# ioam3358 register map
Registers are 32-bit, access not given, no defined reset value unless marked. A register's access mark holds for its fields unless they carry their own. Addresses are absolute; registers are grouped by the start of their names; [hi:lo] are bit positions.

## UART5
0x481AA000 UART5_DLL 8-bit
0x481AA000 UART5_RHR 8-bit
0x481AA000 UART5_THR 8-bit
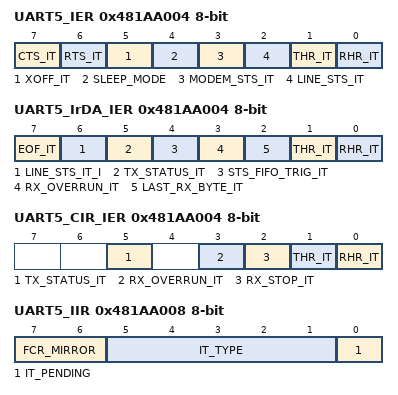
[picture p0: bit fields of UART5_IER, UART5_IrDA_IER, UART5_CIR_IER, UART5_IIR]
0x481AA004 UART5_IER 8-bit
  [7] CTS_IT, [6] RTS_IT, [5] XOFF_IT, [4] SLEEP_MODE, [3] MODEM_STS_IT, [2] LINE_STS_IT, [1] THR_IT, [0] RHR_IT
0x481AA004 UART5_DLH 8-bit
0x481AA004 UART5_IrDA_IER 8-bit
  [7] EOF_IT, [6] LINE_STS_IT_I, [5] TX_STATUS_IT, [4] STS_FIFO_TRIG_IT, [3] RX_OVERRUN_IT, [2] LAST_RX_BYTE_IT, [1] THR_IT, [0] RHR_IT
0x481AA004 UART5_CIR_IER 8-bit
  [5] TX_STATUS_IT, [3] RX_OVERRUN_IT, [2] RX_STOP_IT, [1] THR_IT, [0] RHR_IT
0x481AA008 UART5_IIR 8-bit
  [7:6] FCR_MIRROR, [5:1] IT_TYPE, [0] IT_PENDING
0x481AA008 UART5_FCR 8-bit
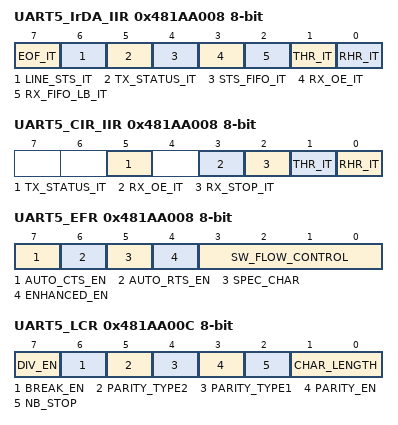
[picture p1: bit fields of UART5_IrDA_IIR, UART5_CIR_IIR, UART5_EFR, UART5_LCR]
0x481AA008 UART5_IrDA_IIR 8-bit
  [7] EOF_IT, [6] LINE_STS_IT, [5] TX_STATUS_IT, [4] STS_FIFO_IT, [3] RX_OE_IT, [2] RX_FIFO_LB_IT, [1] THR_IT, [0] RHR_IT
0x481AA008 UART5_CIR_IIR 8-bit
  [5] TX_STATUS_IT, [3] RX_OE_IT, [2] RX_STOP_IT, [1] THR_IT, [0] RHR_IT
0x481AA008 UART5_EFR 8-bit
  [7] AUTO_CTS_EN, [6] AUTO_RTS_EN, [5] SPEC_CHAR, [4] ENHANCED_EN, [3:0] SW_FLOW_CONTROL
0x481AA00C UART5_LCR 8-bit
  [7] DIV_EN, [6] BREAK_EN, [5] PARITY_TYPE2, [4] PARITY_TYPE1, [3] PARITY_EN, [2] NB_STOP, [1:0] CHAR_LENGTH
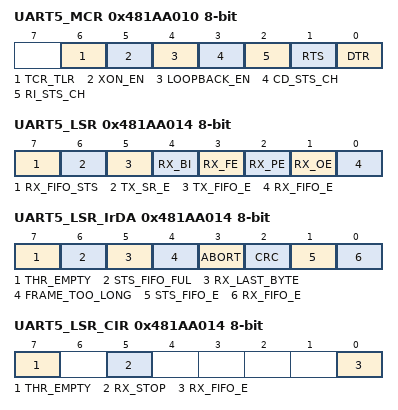
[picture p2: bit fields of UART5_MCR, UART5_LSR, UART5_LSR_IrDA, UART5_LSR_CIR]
0x481AA010 UART5_MCR 8-bit
  [6] TCR_TLR, [5] XON_EN, [4] LOOPBACK_EN, [3] CD_STS_CH, [2] RI_STS_CH, [1] RTS, [0] DTR
0x481AA010 UART5_XON1_ADDR1 8-bit
0x481AA014 UART5_LSR 8-bit
  [7] RX_FIFO_STS, [6] TX_SR_E, [5] TX_FIFO_E, [4] RX_BI, [3] RX_FE, [2] RX_PE, [1] RX_OE, [0] RX_FIFO_E
0x481AA014 UART5_XON2_ADDR2 8-bit
0x481AA014 UART5_LSR_IrDA 8-bit
  [7] THR_EMPTY, [6] STS_FIFO_FUL, [5] RX_LAST_BYTE, [4] FRAME_TOO_LONG, [3] ABORT, [2] CRC, [1] STS_FIFO_E, [0] RX_FIFO_E
0x481AA014 UART5_LSR_CIR 8-bit
  [7] THR_EMPTY, [5] RX_STOP, [0] RX_FIFO_E
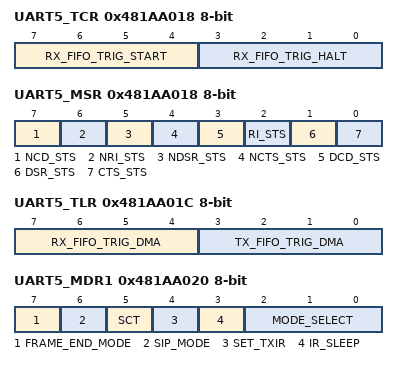
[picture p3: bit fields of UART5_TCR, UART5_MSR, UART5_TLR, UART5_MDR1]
0x481AA018 UART5_TCR 8-bit
  [7:4] RX_FIFO_TRIG_START, [3:0] RX_FIFO_TRIG_HALT
0x481AA018 UART5_XOFF1 8-bit
0x481AA018 UART5_MSR 8-bit
  [7] NCD_STS, [6] NRI_STS, [5] NDSR_STS, [4] NCTS_STS, [3] DCD_STS, [2] RI_STS, [1] DSR_STS, [0] CTS_STS
0x481AA01C UART5_TLR 8-bit
  [7:4] RX_FIFO_TRIG_DMA, [3:0] TX_FIFO_TRIG_DMA
0x481AA01C UART5_SPR 8-bit
0x481AA01C UART5_XOFF2 8-bit
0x481AA020 UART5_MDR1 8-bit
  [7] FRAME_END_MODE, [6] SIP_MODE, [5] SCT, [4] SET_TXIR, [3] IR_SLEEP, [2:0] MODE_SELECT
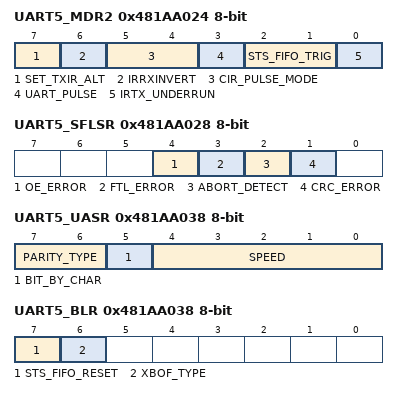
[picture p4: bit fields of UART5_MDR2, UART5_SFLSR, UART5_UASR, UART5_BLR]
0x481AA024 UART5_MDR2 8-bit
  [7] SET_TXIR_ALT, [6] IRRXINVERT, [5:4] CIR_PULSE_MODE, [3] UART_PULSE, [2:1] STS_FIFO_TRIG, [0] IRTX_UNDERRUN
0x481AA028 UART5_SFLSR 8-bit
  [4] OE_ERROR, [3] FTL_ERROR, [2] ABORT_DETECT, [1] CRC_ERROR
0x481AA028 UART5_TXFLL 8-bit
0x481AA02C UART5_TXFLH 8-bit
  [4:0] TXFLH
0x481AA02C UART5_RESUME 8-bit
0x481AA030 UART5_SFREGL 8-bit
0x481AA030 UART5_RXFLL 8-bit
0x481AA034 UART5_SFREGH 8-bit
  [3:0] SFREGH
0x481AA034 UART5_RXFLH 8-bit
  [3:0] RXFLH
0x481AA038 UART5_UASR 8-bit
  [7:6] PARITY_TYPE, [5] BIT_BY_CHAR, [4:0] SPEED
0x481AA038 UART5_BLR 8-bit
  [7] STS_FIFO_RESET, [6] XBOF_TYPE
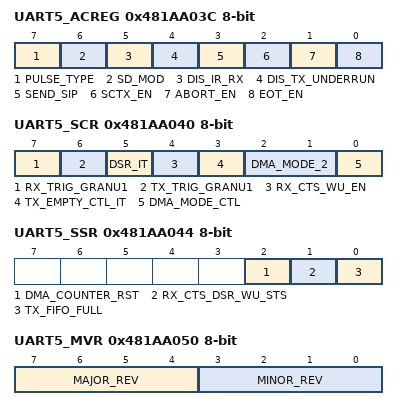
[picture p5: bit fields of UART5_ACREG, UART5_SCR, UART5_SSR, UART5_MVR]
0x481AA03C UART5_ACREG 8-bit
  [7] PULSE_TYPE, [6] SD_MOD, [5] DIS_IR_RX, [4] DIS_TX_UNDERRUN, [3] SEND_SIP, [2] SCTX_EN, [1] ABORT_EN, [0] EOT_EN
0x481AA040 UART5_SCR 8-bit
  [7] RX_TRIG_GRANU1, [6] TX_TRIG_GRANU1, [5] DSR_IT, [4] RX_CTS_WU_EN, [3] TX_EMPTY_CTL_IT, [2:1] DMA_MODE_2, [0] DMA_MODE_CTL
0x481AA044 UART5_SSR 8-bit
  [2] DMA_COUNTER_RST, [1] RX_CTS_DSR_WU_STS, [0] TX_FIFO_FULL
0x481AA048 UART5_EBLR 8-bit
0x481AA050 UART5_MVR 8-bit
  [7:4] MAJOR_REV, [3:0] MINOR_REV
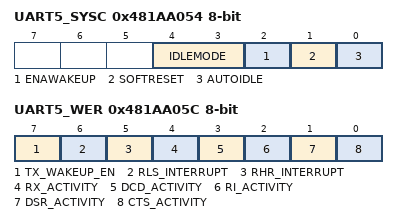
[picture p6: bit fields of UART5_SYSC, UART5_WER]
0x481AA054 UART5_SYSC 8-bit
  [4:3] IDLEMODE, [2] ENAWAKEUP, [1] SOFTRESET, [0] AUTOIDLE
0x481AA058 UART5_SYSS 8-bit
  [0] RESETDONE
0x481AA05C UART5_WER 8-bit
  [7] TX_WAKEUP_EN, [6] RLS_INTERRUPT, [5] RHR_INTERRUPT, [4] RX_ACTIVITY, [3] DCD_ACTIVITY, [2] RI_ACTIVITY, [1] DSR_ACTIVITY, [0] CTS_ACTIVITY
0x481AA060 UART5_CFPS 8-bit

## DMTIMER0
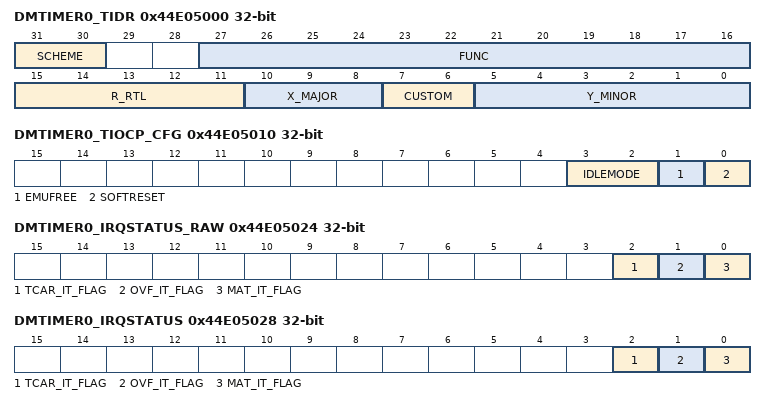
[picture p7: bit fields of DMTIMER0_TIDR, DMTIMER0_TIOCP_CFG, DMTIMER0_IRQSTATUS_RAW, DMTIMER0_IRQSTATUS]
0x44E05000 DMTIMER0_TIDR
  [31:30] SCHEME, [27:16] FUNC, [15:11] R_RTL, [10:8] X_MAJOR, [7:6] CUSTOM, [5:0] Y_MINOR
0x44E05010 DMTIMER0_TIOCP_CFG
  [3:2] IDLEMODE, [1] EMUFREE, [0] SOFTRESET
0x44E05020 DMTIMER0_IRQ_EOI
  [0] LINE_NUMBER
0x44E05024 DMTIMER0_IRQSTATUS_RAW
  [2] TCAR_IT_FLAG, [1] OVF_IT_FLAG, [0] MAT_IT_FLAG
0x44E05028 DMTIMER0_IRQSTATUS
  [2] TCAR_IT_FLAG, [1] OVF_IT_FLAG, [0] MAT_IT_FLAG
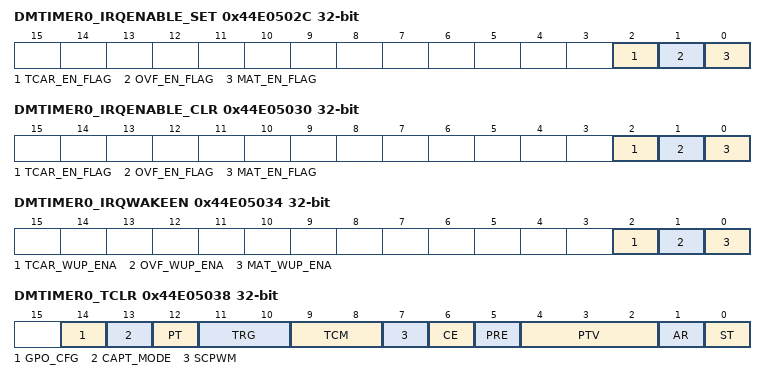
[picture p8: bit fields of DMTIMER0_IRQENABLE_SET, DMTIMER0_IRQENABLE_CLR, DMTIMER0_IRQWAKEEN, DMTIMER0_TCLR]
0x44E0502C DMTIMER0_IRQENABLE_SET
  [2] TCAR_EN_FLAG, [1] OVF_EN_FLAG, [0] MAT_EN_FLAG
0x44E05030 DMTIMER0_IRQENABLE_CLR
  [2] TCAR_EN_FLAG, [1] OVF_EN_FLAG, [0] MAT_EN_FLAG
0x44E05034 DMTIMER0_IRQWAKEEN
  [2] TCAR_WUP_ENA, [1] OVF_WUP_ENA, [0] MAT_WUP_ENA
0x44E05038 DMTIMER0_TCLR
  [14] GPO_CFG, [13] CAPT_MODE, [12] PT, [11:10] TRG, [9:8] TCM, [7] SCPWM, [6] CE, [5] PRE, [4:2] PTV, [1] AR, [0] ST
0x44E0503C DMTIMER0_TCRR
0x44E05040 DMTIMER0_TLDR
0x44E05044 DMTIMER0_TTGR
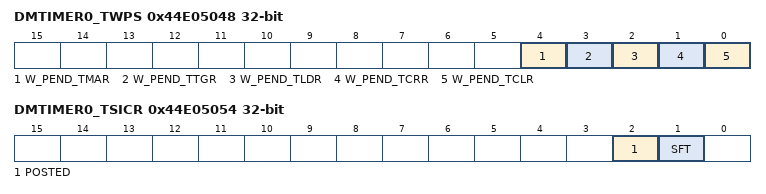
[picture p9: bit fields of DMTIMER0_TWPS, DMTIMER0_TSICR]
0x44E05048 DMTIMER0_TWPS
  [4] W_PEND_TMAR, [3] W_PEND_TTGR, [2] W_PEND_TLDR, [1] W_PEND_TCRR, [0] W_PEND_TCLR
0x44E0504C DMTIMER0_TMAR
0x44E05050 DMTIMER0_TCAR1
0x44E05054 DMTIMER0_TSICR
  [2] POSTED, [1] SFT
0x44E05058 DMTIMER0_TCAR2
